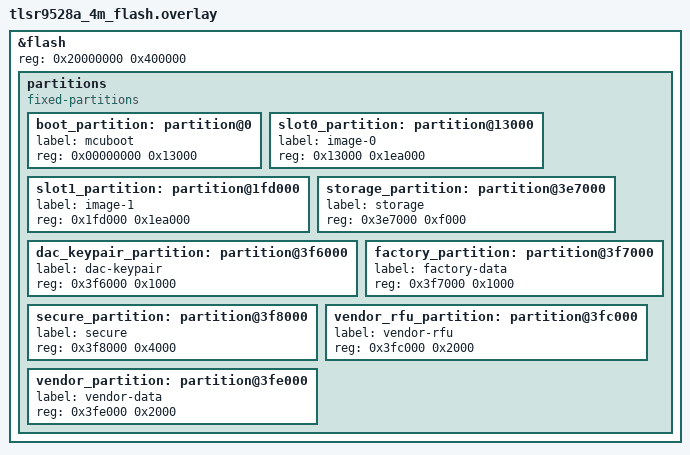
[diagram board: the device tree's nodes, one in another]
&flash {
	reg = <0x20000000 0x400000>;

	/delete-node/ partitions;
	partitions {
		compatible = "fixed-partitions";
		#address-cells = <1>;
		#size-cells = <1>;

		boot_partition: partition@0 {
			label = "mcuboot";
			reg = <0x00000000 0x13000>;
		};
		slot0_partition: partition@13000 {
			label = "image-0";
			reg = <0x13000 0x1ea000>;
		};
		slot1_partition: partition@1fd000 {
			label = "image-1";
			reg = <0x1fd000 0x1ea000>;
		};
		storage_partition: partition@3e7000 {
			label = "storage";
			reg = <0x3e7000 0xf000>; // matter nvs part 
		};
		dac_keypair_partition: partition@3f6000 {
			label = "dac-keypair";
			reg = <0x3f6000 0x1000>; // store dac and key pair.
		};
		factory_partition: partition@3f7000 {
			label = "factory-data";
			reg = <0x3f7000 0x1000>; // factory data info.
		};
		secure_partition: partition@3f8000 {
 			label = "secure";
			reg = <0x3f8000 0x4000>; // secure info, reserved for secure boot. if not use, can be used by other way.
 		};
		vendor_rfu_partition: partition@3fc000 {
			label = "vendor-rfu";
			reg = <0x3fc000 0x2000>; // reserved for chip extend.
		};
		vendor_partition: partition@3fe000 {
			label = "vendor-data";
			reg = <0x3fe000 0x2000>; // mac and adc info.
		};
	};
};
